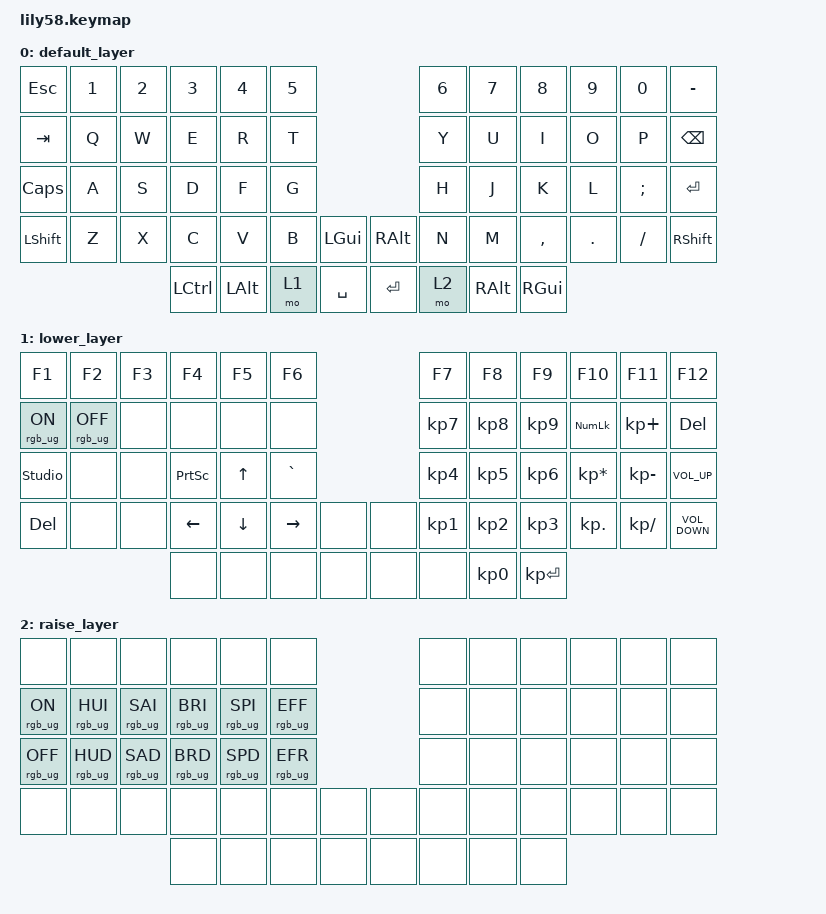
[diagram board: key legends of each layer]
/*
 * Copyright (c) 2020 The ZMK Contributors
 *
 * SPDX-License-Identifier: MIT
 */
#include <input/processors.dtsi>
#include <zephyr/dt-bindings/input/input-event-codes.h>
#include <dt-bindings/zmk/outputs.h>
#include <dt-bindings/zmk/rgb.h>
#include <dt-bindings/zmk/backlight.h>

#include <behaviors.dtsi>
#include <dt-bindings/zmk/keys.h>
#include <dt-bindings/zmk/bt.h>
#include <dt-bindings/zmk/ext_power.h>

&led_strip { chain-length = <33>; };
/ {
    keymap {
        compatible = "zmk,keymap";

        default_layer { 
// ------------------------------------------------------------------------------------------------------------
// |  ESC  |  1  |  2  |  3   |  4   |  5   |                   |  6   |  7    |  8    |  9   |   0   | MINUS |
// |  TAB  |  Q  |  W  |  E   |  R   |  T   |                   |  Y   |  U    |  I    |  O   |   P   | BSPC  |
// | MAYUS |  A  |  S  |  D   |  F   |  G   |                   |  H   |  J    |  K    |  L   |   ;   | ENTER |
// | SHIFT |  Z  |  X  |  C   |  V   |  B   |   GUI  |  |  ALT  |  N   |  M    |  ,    |  .   |   /   | SHIFT |
//                     | CTRL  | ALT  | LOWER|  SPACE |  | ENTER | RAISE| BSPC  | GUI   |
            bindings = <
&kp ESC   &kp NUMBER_1   &kp NUMBER_2   &kp NUMBER_3   &kp NUMBER_4   &kp NUMBER_5                  &kp NUMBER_6   &kp NUMBER_7   &kp NUMBER_8   &kp NUMBER_9   &kp NUMBER_0   &kp MINUS
&kp TAB   &kp Q          &kp W          &kp E          &kp R          &kp T                         &kp Y          &kp U          &kp I          &kp O          &kp P          &kp BSPC
&kp CAPS  &kp A          &kp S          &kp D          &kp F          &kp G                         &kp H          &kp J          &kp K          &kp L          &kp SEMI       &kp ENTER
&kp LSHFT &kp Z          &kp X          &kp C          &kp V          &kp B   &kp LGUI   &kp RALT   &kp N          &kp M          &kp COMMA      &kp DOT        &kp FSLH       &kp RSHFT
                                        &kp LCTRL      &kp LALT       &mo 1  &kp SPACE   &kp RET    &mo 2          &kp RALT       &kp RGUI
            >;

            sensor-bindings = <&inc_dec_kp C_VOL_UP C_VOL_DN>;
        };

        lower_layer {

// ------------------------------------------------------------------------------------------------------------
// |  F1   |  F2 |  F3 |  F4  |  F5  |  F6  |                   |  F7  |  F8   |  F9   |  F10 |  F11  |  F12  |
// |       |     |     |      |      |      |                   |  7   |   8   |  9    | NLCK |   +   |  DEL  |
// | UNLKST|     |     | PRINT|  UP  | GRAVE|                   |  4   |   5   |  6    |  *   |   -   | VOL_UP|
// |  DEL  |     |     | LEFT | DOWN | RIGHT|        |  |       |  1   |   2   |  3    |  .   |   /   | VOL_DN|
//                     |      |      |      |        |  |       |      |   0   | ENTER |
            bindings = <
&kp F1     &kp F2           &kp F3    &kp F4            &kp F5         &kp F6                                 &kp F7            &kp F8             &kp F9             &kp F10         &kp F11      &kp F12
&rgb_ug RGB_ON &rgb_ug RGB_OFF     &none     &none             &none          &none                                  &kp KP_NUMBER_7   &kp KP_NUMBER_8    &kp KP_NUMBER_9    &kp KP_NUMLOCK  &kp KP_PLUS  &kp DELETE 
&studio_unlock&none         &none     &kp PRINTSCREEN   &kp UP_ARROW   &kp GRAVE                              &kp KP_NUMBER_4   &kp KP_NUMBER_5    &kp KP_NUMBER_6    &kp KP_MULTIPLY &kp KP_MINUS &kp C_VOLUME_UP
&kp DELETE &none            &none     &kp LEFT_ARROW    &kp DOWN_ARROW &kp RIGHT_ARROW  &none        &none    &kp KP_NUMBER_1   &kp KP_NUMBER_2    &kp KP_NUMBER_3    &kp KP_DOT      &kp KP_DIVIDE &kp C_VOLUME_DOWN
                                      &none             &none          &none            &none        &none    &none             &kp KP_NUMBER_0    &kp KP_ENTER
            >;

            sensor-bindings = <&inc_dec_kp C_VOL_UP C_VOL_DN>;
        };

        raise_layer {
// ------------------------------------------------------------------------------------------------------------
// |       |       |     |      |      |      |                   |       |       |     |      |      |      | 
// |RGB_ON |   HUI | SAI |  BRI |  SPI |  EFF |                   |       |       |     |      |      |      | 
// |RGB_OFF|  HUD  | SAD |  BRD |  SPD |  EFR |                   |       |       |     |      |      |      | 
// |   HSB |       |     |      |      |      |        |  |       |       |       |     |      |      |      | 
//                       |      |      |      |        |  |       |       |       |     |
            bindings = <
&none               &none               &none             &none              &none             &none                                &none               &none               &none             &none                &none          &none
&rgb_ug RGB_ON      &rgb_ug RGB_HUI     &rgb_ug RGB_SAI   &rgb_ug RGB_BRI    &rgb_ug RGB_SPI   &rgb_ug RGB_EFF                      &none               &none               &none             &none                &none          &none
&rgb_ug RGB_OFF     &rgb_ug RGB_HUD     &rgb_ug RGB_SAD   &rgb_ug RGB_BRD    &rgb_ug RGB_SPD   &rgb_ug RGB_EFR                      &none               &none               &none             &none                &none          &none
&none &none             &none             &none              &none             &none             &none  &none       &none               &none               &none             &none                &none          &none
                                                          &none              &none             &none             &none  &none       &none               &none               &none
            >;

            sensor-bindings = <&inc_dec_kp C_VOL_UP C_VOL_DN>;
        };
    };
};
